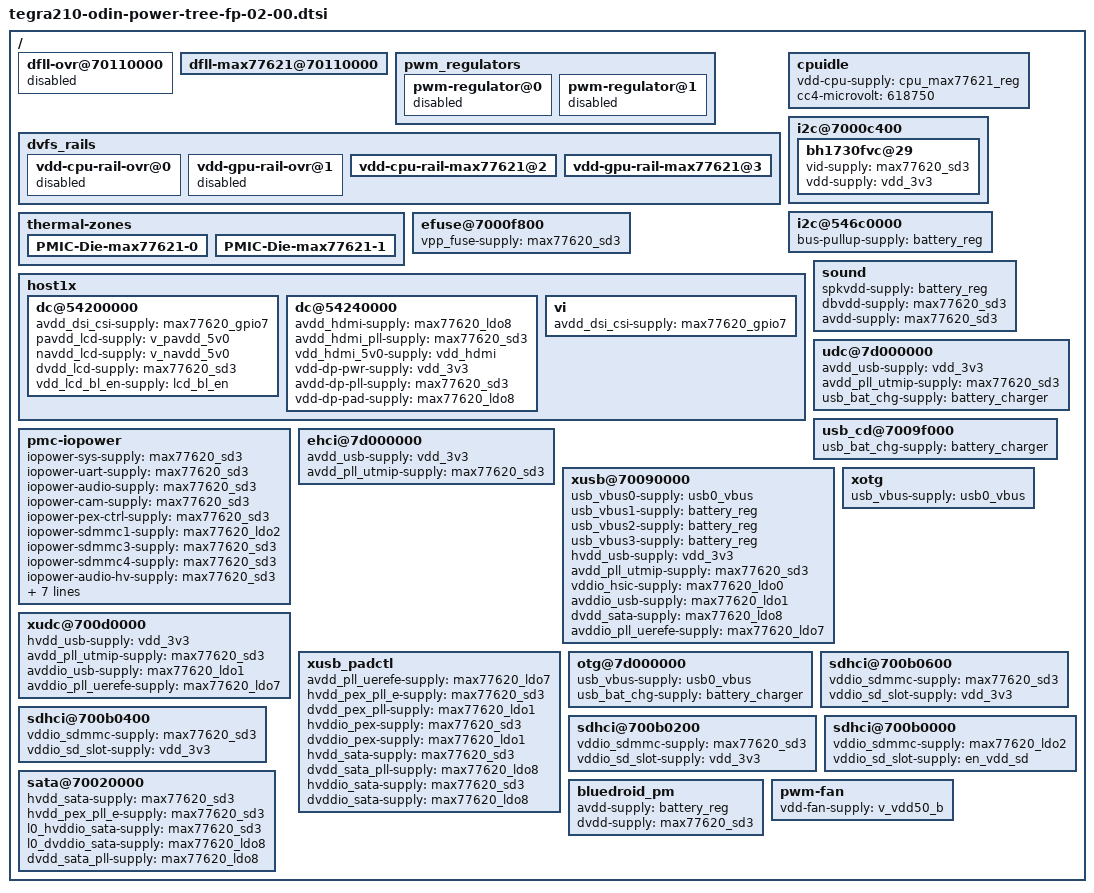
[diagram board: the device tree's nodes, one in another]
/*
 * Copyright (c) 2014-2015, NVIDIA CORPORATION.  All rights reserved.
 *
 * This program is free software; you can redistribute it and/or modify
 * it under the terms of the GNU General Public License as published by
 * the Free Software Foundation; either version 2 of the License, or
 * (at your option) any later version.
 *
 * This program is distributed in the hope that it will be useful, but WITHOUT
 * ANY WARRANTY; without even the implied warranty of MERCHANTABILITY or
 * FITNESS FOR A PARTICULAR PURPOSE.  See the GNU General Public License for
 * more details.
 *
 * You should have received a copy of the GNU General Public License along
 * along with this program. If not, see <http://www.gnu.org/licenses/>.
 */

#include "tegra210-odin-pmic-fp-02-00.dtsi"
#include "tegra210-odin-power-fixed-fp-02-00.dtsi"
#include "tegra210-ers-power-dvfs-e2174-1101-a00.dtsi"

/ {

	dfll-ovr@70110000 {
		status = "disabled";
	};

	dfll-max77621@70110000 {
		status = "okay";
	};

	pwm_regulators {
		pwm-regulator@0 {
			status = "disabled";
		};

		pwm-regulator@1 {
			status = "disabled";
		};
	};

	dvfs_rails {
		vdd-cpu-rail-ovr@0 {
			status = "disabled";
		};

		vdd-gpu-rail-ovr@1 {
			status = "disabled";
		};

		vdd-cpu-rail-max77621@2 {
			status = "okay";
		};

		vdd-gpu-rail-max77621@3 {
			status = "okay";
		};
	};

	cpuidle {
		vdd-cpu-supply = <&cpu_max77621_reg>;
		cc4-microvolt = <618750>;
	};

	thermal-zones {
		PMIC-Die-max77621-0 {
			status = "okay";
		};

		PMIC-Die-max77621-1 {
			status = "okay";
		};
	};

	i2c@7000c400 {
		bh1730fvc@29 {
			vid-supply = <&max77620_sd3>;
			vdd-supply = <&vdd_3v3>;
		};
	};

	i2c@546c0000 {
		bus-pullup-supply = <&battery_reg>;
	};

	efuse@7000f800 {
		vpp_fuse-supply = <&max77620_sd3>;
	};

	host1x {
		/* tegradc.0 */
		dc@54200000 {
			avdd_dsi_csi-supply = <&max77620_gpio7>;
			pavdd_lcd-supply = <&v_pavdd_5v0>;
			navdd_lcd-supply = <&v_navdd_5v0>;
			dvdd_lcd-supply = <&max77620_sd3>;
			vdd_lcd_bl_en-supply = <&lcd_bl_en>;
		};

		/* tegradc.1 */
		dc@54240000 {
			avdd_hdmi-supply = <&max77620_ldo8>;    /* 1V05 */
			avdd_hdmi_pll-supply = <&max77620_sd3>; /* 1V8 */
			vdd_hdmi_5v0-supply = <&vdd_hdmi>;	/* 5V0 GPIO_PCC7 fixed reg */
			/* dp */
			vdd-dp-pwr-supply = <&vdd_3v3>;
			avdd-dp-pll-supply = <&max77620_sd3>;
			vdd-dp-pad-supply = <&max77620_ldo8>;
		};

		vi {
			avdd_dsi_csi-supply = <&max77620_gpio7>;
		};
	};

	sound {
		spkvdd-supply = <&battery_reg>;
		dbvdd-supply = <&max77620_sd3>;
		avdd-supply = <&max77620_sd3>;
	};

	pmc-iopower {
		iopower-sys-supply = <&max77620_sd3>;
		iopower-uart-supply = <&max77620_sd3>;
		iopower-audio-supply = <&max77620_sd3>;
		iopower-cam-supply = <&max77620_sd3>;
		iopower-pex-ctrl-supply = <&max77620_sd3>;
		iopower-sdmmc1-supply = <&max77620_ldo2>;
		iopower-sdmmc3-supply = <&max77620_sd3>;
		iopower-sdmmc4-supply = <&max77620_sd3>;
		iopower-audio-hv-supply = <&max77620_sd3>;
		iopower-debug-supply = <&max77620_sd3>;
		iopower-dmic-supply = <&max77620_sd3>;
		iopower-gpio-supply = <&vdd_3v3>;
		iopower-spi-supply = <&max77620_sd3>;
		iopower-spi-hv-supply = <&max77620_sd3>;
		iopower-sdmmc2-supply = <&max77620_sd3>;
		iopower-dp-supply = <&max77620_sd3>;
	};

	udc@7d000000 {
		avdd_usb-supply = <&vdd_3v3>;
		avdd_pll_utmip-supply = <&max77620_sd3>;
		usb_bat_chg-supply = <&battery_charger>;
	};

	usb_cd@7009f000 {
		usb_bat_chg-supply = <&battery_charger>;
	};

	ehci@7d000000 {
		avdd_usb-supply = <&vdd_3v3>;
		avdd_pll_utmip-supply = <&max77620_sd3>;
	};

	xusb@70090000 {
		usb_vbus0-supply = <&usb0_vbus>;
		usb_vbus1-supply = <&battery_reg>;
		usb_vbus2-supply = <&battery_reg>;
		usb_vbus3-supply = <&battery_reg>;
		hvdd_usb-supply = <&vdd_3v3>;
		avdd_pll_utmip-supply = <&max77620_sd3>;
		vddio_hsic-supply = <&max77620_ldo0>;
		avddio_usb-supply = <&max77620_ldo1>;
		dvdd_sata-supply = <&max77620_ldo8>;
		avddio_pll_uerefe-supply = <&max77620_ldo7>;
	};

	xudc@700d0000 {
		hvdd_usb-supply = <&vdd_3v3>;
		avdd_pll_utmip-supply = <&max77620_sd3>;
		avddio_usb-supply = <&max77620_ldo1>;
		avddio_pll_uerefe-supply = <&max77620_ldo7>;
        };

	xotg {
		usb_vbus-supply = <&usb0_vbus>;
	};

	xusb_padctl {
		avdd_pll_uerefe-supply = <&max77620_ldo7>;
		hvdd_pex_pll_e-supply = <&max77620_sd3>;
		dvdd_pex_pll-supply = <&max77620_ldo1>;
		hvddio_pex-supply = <&max77620_sd3>;
		dvddio_pex-supply = <&max77620_ldo1>;
		hvdd_sata-supply = <&max77620_sd3>;
		dvdd_sata_pll-supply = <&max77620_ldo8>;
		hvddio_sata-supply = <&max77620_sd3>;
		dvddio_sata-supply = <&max77620_ldo8>;
	};

	otg@7d000000 {
		usb_vbus-supply = <&usb0_vbus>;
		usb_bat_chg-supply = <&battery_charger>;
	};

	sdhci@700b0600 {
		vddio_sdmmc-supply = <&max77620_sd3>;
		vddio_sd_slot-supply = <&vdd_3v3>;
	};

	sdhci@700b0400 {
		vddio_sdmmc-supply = <&max77620_sd3>;
		vddio_sd_slot-supply = <&vdd_3v3>;
	};

	sdhci@700b0200 {
		vddio_sdmmc-supply = <&max77620_sd3>;
		vddio_sd_slot-supply = <&vdd_3v3>;
	};

	sdhci@700b0000 {
		vddio_sdmmc-supply = <&max77620_ldo2>;
		vddio_sd_slot-supply = <&en_vdd_sd>;
	};

	sata@70020000 {
		hvdd_sata-supply = <&max77620_sd3>;
		hvdd_pex_pll_e-supply = <&max77620_sd3>;
		l0_hvddio_sata-supply = <&max77620_sd3>;
		l0_dvddio_sata-supply = <&max77620_ldo8>;
		dvdd_sata_pll-supply = <&max77620_ldo8>;
	};

	bluedroid_pm {
		avdd-supply = <&battery_reg>;
		dvdd-supply = <&max77620_sd3>;
	};

	pwm-fan {
		vdd-fan-supply = <&v_vdd50_b>;
	};
};
